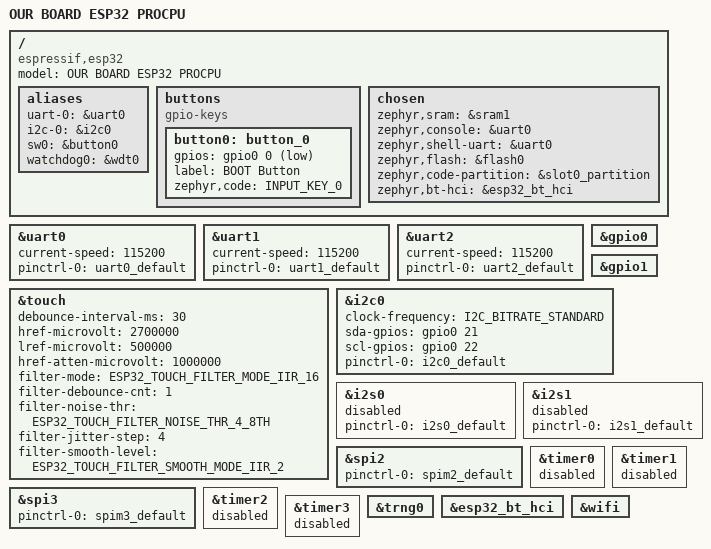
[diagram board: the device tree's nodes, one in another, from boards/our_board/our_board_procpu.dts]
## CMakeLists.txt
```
cmake_minimum_required(VERSION 3.20.0)

# Register this application directory as a board root so the custom board in
# <app>/boards/our_board can be discovered without --board-dir.
# See Zephyr RTOS course, Lecture 5: Custom Boards.
list(APPEND BOARD_ROOT ${CMAKE_CURRENT_SOURCE_DIR})

# Pick up the out-of-tree LED sensor driver module that ships with this app.
# See Zephyr RTOS course, Lecture 6: Zephyr Driver Development.
list(APPEND EXTRA_ZEPHYR_MODULES ${CMAKE_CURRENT_SOURCE_DIR}/drivers/my_driver_module)

find_package(Zephyr REQUIRED)
project(my_zephyr_app)

target_sources(app PRIVATE src/main.c)
```

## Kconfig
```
menuconfig LED_SUBSYSTEM
	bool "LED Subsystem"
	default y

if LED_SUBSYSTEM

choice
	prompt "LED blink sleep time"
	default BLINK_SLEEP_1000MS

config BLINK_SLEEP_250MS
	bool "Fast (250ms)"

config BLINK_SLEEP_500MS
	bool "Medium (500ms)"

config BLINK_SLEEP_1000MS
	bool "Medium (1s)"

config BLINK_SLEEP_2000MS
	bool "Slow (2s)"

endchoice

config BLINK_SLEEP_TIME_MS
	int
	default 250 if BLINK_SLEEP_250MS
	default 500 if BLINK_SLEEP_500MS
	default 1000 if BLINK_SLEEP_1000MS
	default 2000 if BLINK_SLEEP_2000MS
	default 1000

menuconfig LED_ADVANCED
	bool "Advanced LED settings"
	default n

if LED_ADVANCED

config LED_BRIGHTNESS
	int "LED brightness (0-100)"
	range 0 100
	default 100

config LED_FADE_DURATION_MS
	int "LED fade duration (ms)"
	range 0 5000
	default 500

menu "Expert settings"
	visible if LED_ADVANCED

config LED_DEBUG
	bool "Enable LED debugging"
	default n

config LED_CUSTOM_PATTERN
	bool "Custom blink pattern"
	default n

endmenu

endif # LED_ADVANCED

endif # LED_SUBSYSTEM

config APP_HEARTBEAT_PERIOD_MS
	int "Heartbeat LED period (ms)"
	default 500
	range 100 2000

source "Kconfig.zephyr"
```

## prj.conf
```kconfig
CONFIG_SERIAL=y
CONFIG_CONSOLE=y
CONFIG_UART_CONSOLE=y
CONFIG_PRINTK=y

CONFIG_SENSOR=y
CONFIG_GPIO=y
CONFIG_LOG=y
CONFIG_SENSOR_LOG_LEVEL_INF=y

CONFIG_SHELL=y
```

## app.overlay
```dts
#include <zephyr/dt-bindings/gpio/gpio.h>

/ {

    led_sensor_node: led_sensor {
        compatible = "my,led-sensor";
        led-gpios = < &gpio0 2 GPIO_ACTIVE_HIGH>;
        status = "okay";
    };
};
```

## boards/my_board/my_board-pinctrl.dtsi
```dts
/*
 * Copyright (c) 2022-2025 Espressif Systems (Shanghai) Co., Ltd.
 *
 * SPDX-License-Identifier: Apache-2.0
 */

#include <zephyr/dt-bindings/pinctrl/esp-pinctrl-common.h>
#include <dt-bindings/pinctrl/esp32-pinctrl.h>
#include <zephyr/dt-bindings/pinctrl/esp32-gpio-sigmap.h>

&pinctrl {

	uart0_default: uart0_default {
		group1 {
			pinmux = <UART0_TX_GPIO1>;
			output-high;
		};
		group2 {
			pinmux = <UART0_RX_GPIO3>;
			bias-pull-up;
		};
	};
};
```

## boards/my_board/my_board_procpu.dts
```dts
/*
 * Copyright (c) 2025
 *
 * SPDX-License-Identifier: Apache-2.0
 */

/dts-v1/;

#include <espressif/esp32/esp32_wrover_e_n4r8.dtsi>
#include "my_board-pinctrl.dtsi"
#include <espressif/partitions_0x1000_amp.dtsi>

/ {
	model = "MY BOARD";
	compatible = "espressif,esp32";

	chosen {
		zephyr,sram = &sram1;
		zephyr,console = &uart0;
		zephyr,shell-uart = &uart0;
		zephyr,flash = &flash0;
		zephyr,code-partition = &slot0_partition;
	};
};

&uart0 {
	status = "okay";
	current-speed = <115200>;
	pinctrl-0 = <&uart0_default>;
	pinctrl-names = "default";
};

&gpio0 {
	status = "okay";
};

&gpio1 {
	status = "okay";
};
```

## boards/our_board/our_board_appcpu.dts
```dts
/*
 * Copyright (c) 2023-2025 Espressif Systems (Shanghai) Co., Ltd.
 *
 * SPDX-License-Identifier: Apache-2.0
 */
/dts-v1/;

#include <espressif/esp32/esp32_appcpu.dtsi>
#include <espressif/partitions_0x1000_amp.dtsi>

/ {
	model = "OUR BOARD ESP32 APPCPU";
	compatible = "espressif,esp32";

	chosen {
		zephyr,sram = &sram1;
		zephyr,ipc_shm = &shm0;
		zephyr,ipc = &ipm0;
		zephyr,flash = &flash0;
		zephyr,code-partition = &slot0_appcpu_partition;
	};
};

&ipm0 {
	status = "okay";
};

&trng0 {
	status = "okay";
};
```

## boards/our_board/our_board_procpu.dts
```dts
/*
 * Copyright (c) 2023-2025 Espressif Systems (Shanghai) Co., Ltd.
 *
 * SPDX-License-Identifier: Apache-2.0
 */
/dts-v1/;

#include <espressif/esp32/esp32_wrover_e_n4r8.dtsi>
#include "esp32_devkitc-pinctrl.dtsi"
#include <zephyr/dt-bindings/input/input-event-codes.h>
#include <zephyr/dt-bindings/input/esp32-touch-sensor-input.h>
#include <espressif/partitions_0x1000_amp.dtsi>

/ {
	model = "OUR BOARD ESP32 PROCPU";
	compatible = "espressif,esp32";

	aliases {
		uart-0 = &uart0;
		i2c-0 = &i2c0;
		sw0 = &button0;
		watchdog0 = &wdt0;
	};

	buttons {
		compatible = "gpio-keys";
		button0: button_0 {
			gpios = <&gpio0 0 (GPIO_PULL_UP | GPIO_ACTIVE_LOW)>;
			label = "BOOT Button";
			zephyr,code = <INPUT_KEY_0>;
		};
	};

	chosen {
		zephyr,sram = &sram1;
		zephyr,console = &uart0;
		zephyr,shell-uart = &uart0;
		zephyr,flash = &flash0;
		zephyr,code-partition = &slot0_partition;
		zephyr,bt-hci = &esp32_bt_hci;
	};
};

&uart0 {
	status = "okay";
	current-speed = <115200>;
	pinctrl-0 = <&uart0_default>;
	pinctrl-names = "default";
};

&uart1 {
	current-speed = <115200>;
	pinctrl-0 = <&uart1_default>;
	pinctrl-names = "default";
};

&uart2 {
	current-speed = <115200>;
	pinctrl-0 = <&uart2_default>;
	pinctrl-names = "default";
};

&gpio0 {
	status = "okay";
};

&gpio1 {
	status = "okay";
};

&touch {
	debounce-interval-ms = <30>;
	href-microvolt = <2700000>;
	lref-microvolt = <500000>;
	href-atten-microvolt = <1000000>;
	filter-mode = <ESP32_TOUCH_FILTER_MODE_IIR_16>;
	filter-debounce-cnt = <1>;
	filter-noise-thr = <ESP32_TOUCH_FILTER_NOISE_THR_4_8TH>;
	filter-jitter-step = <4>;
	filter-smooth-level = <ESP32_TOUCH_FILTER_SMOOTH_MODE_IIR_2>;
};

&i2c0 {
	status = "okay";
	clock-frequency = <I2C_BITRATE_STANDARD>;
	sda-gpios = <&gpio0 21 GPIO_OPEN_DRAIN>;
	scl-gpios = <&gpio0 22 GPIO_OPEN_DRAIN>;
	pinctrl-0 = <&i2c0_default>;
	pinctrl-names = "default";
};

&i2s0 {
	pinctrl-0 = <&i2s0_default>;
	pinctrl-names = "default";
	status = "disabled";
};

&i2s1 {
	pinctrl-0 = <&i2s1_default>;
	pinctrl-names = "default";
	status = "disabled";
};

&spi2 {
	#address-cells = <1>;
	#size-cells = <0>;
	status = "okay";
	pinctrl-0 = <&spim2_default>;
	pinctrl-names = "default";
};

&spi3 {
	#address-cells = <1>;
	#size-cells = <0>;
	status = "okay";
	pinctrl-0 = <&spim3_default>;
	pinctrl-names = "default";
};

&timer0 {
	status = "disabled";
};

&timer1 {
	status = "disabled";
};

&timer2 {
	status = "disabled";
};

&timer3 {
	status = "disabled";
};

&trng0 {
	status = "okay";
};

&esp32_bt_hci {
	status = "okay";
};

&wifi {
	status = "okay";
};
```

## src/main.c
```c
#include <zephyr/kernel.h>
#include <zephyr/device.h>
#include <zephyr/drivers/sensor.h>
#include <zephyr/sys/printk.h>
#include <my_sensor/led_sensor.h>

int main(void)
{
    const struct device *dev = DEVICE_DT_GET(DT_NODELABEL(led_sensor_node));

    if (!device_is_ready(dev))
    {
        printk("Led Sensor not ready...\n");
    }

    printk("LED sensor driver initialized...Changing parameter...Starting loop...\n");

    int newValue = 50;

    while (1)
    {

        led_sensor_set_param(dev, newValue);
        newValue += 10;
        /* Turn LED ON */
        sensor_sample_fetch(dev);
        k_msleep(1000);

        /* Turn LED OFF and read state */
        struct sensor_value val;
        sensor_channel_get(dev, SENSOR_CHAN_ALL, &val);
        printk("Read -> sensor state: %d & sensor custom value: %d\n", val.val1, val.val2);
        k_msleep(1000);
    }

    return 0;
}
```

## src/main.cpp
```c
#include <zephyr/drivers/gpio.h>
#include <zephyr/kernel.h>
#include <zephyr/logging/log.h>

/* The devicetree node identifier for the "app-led" alias. */
#define LED_NODE DT_ALIAS(app_led)

static const struct gpio_dt_spec led = GPIO_DT_SPEC_GET(LED_NODE, gpios);

LOG_MODULE_REGISTER(main, LOG_LEVEL_INF);

int main(void)
{
    bool led_state = true;

    if (!gpio_is_ready_dt(&led)) return 0;

    if (gpio_pin_configure_dt(&led, GPIO_OUTPUT_ACTIVE) < 0) return 0;

    while (1) {
        if (gpio_pin_toggle_dt(&led) < 0) return 0;

        led_state = !led_state;
        LOG_INF("LED state: %s", led_state ? "ON" : "OFF");
        k_msleep(CONFIG_APP_HEARTBEAT_PERIOD_MS);
    }
    return 0;
}
```
